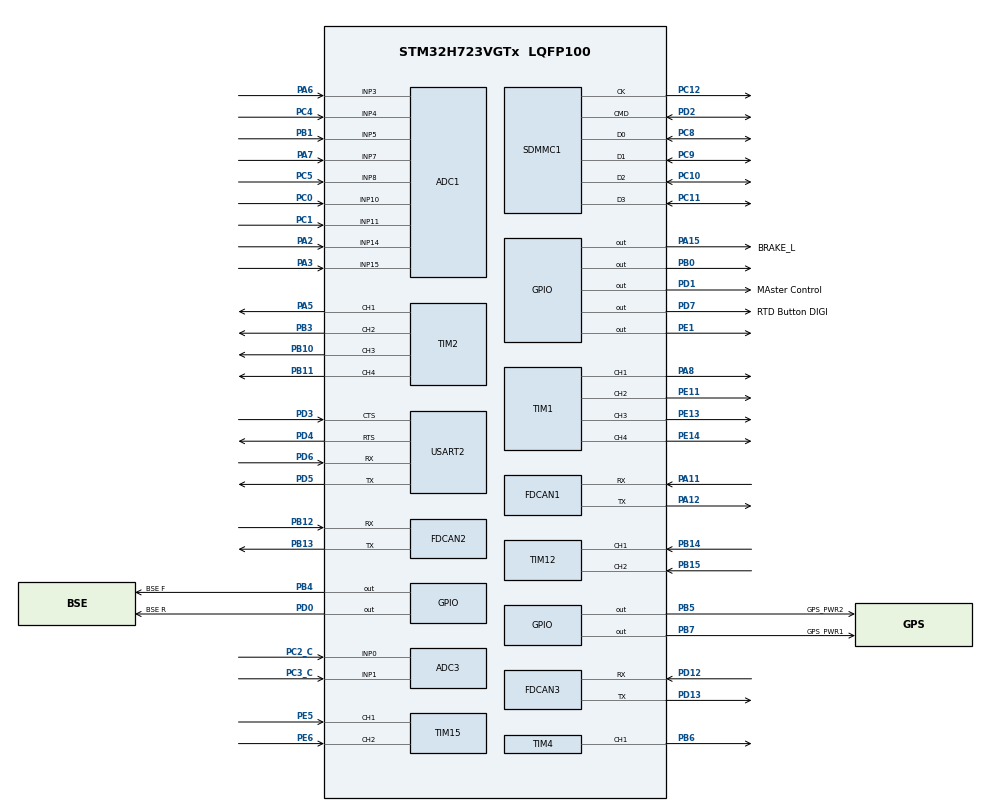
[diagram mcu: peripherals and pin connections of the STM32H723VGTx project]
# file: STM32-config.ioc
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ADC1.Channel-0\#ChannelRegularConversion=ADC_CHANNEL_15
ADC1.ClockPrescaler=ADC_CLOCK_SYNC_PCLK_DIV4
ADC1.ContinuousConvMode=ENABLE
ADC1.ConversionDataManagement=ADC_CONVERSIONDATA_DMA_CIRCULAR
ADC1.DMAAccessModeView=ENABLE
ADC1.Mode=ADC_DUALMODE_REGSIMULT
ADC1.NbrOfConversion=1
ADC1.NbrOfConversionFlag=1
ADC1.OffsetNumber-0\#ChannelRegularConversion=ADC_OFFSET_NONE
ADC1.OffsetSignedSaturation-0\#ChannelRegularConversion=DISABLE
ADC1.OversamplingMode=DISABLE
ADC1.Rank-0\#ChannelRegularConversion=1
ADC1.Ratio=1
ADC1.SamplingTime-0\#ChannelRegularConversion=ADC_SAMPLETIME_64CYCLES_5
ADC1.master=1
ADC2.Channel-0\#ChannelRegularConversion=ADC_CHANNEL_15
ADC2.ClockPrescaler=ADC_CLOCK_SYNC_PCLK_DIV4
ADC2.ContinuousConvMode=ENABLE
ADC2.ConversionDataManagement=ADC_CONVERSIONDATA_DMA_CIRCULAR
ADC2.DMAAccessModeView=ENABLE
ADC2.Mode=ADC_DUALMODE_REGSIMULT
ADC2.NbrOfConversionFlag=1
ADC2.OffsetNumber-0\#ChannelRegularConversion=ADC_OFFSET_NONE
ADC2.OffsetSignedSaturation-0\#ChannelRegularConversion=DISABLE
ADC2.Rank-0\#ChannelRegularConversion=1
ADC2.SamplingTime-0\#ChannelRegularConversion=ADC_SAMPLETIME_64CYCLES_5
ADC3.Channel-0\#ChannelRegularConversion=ADC_CHANNEL_0
ADC3.ClockPrescaler=ADC_CLOCK_SYNC_PCLK_DIV4
ADC3.DMAAccessModeView=ENABLE
ADC3.Mode=ADC_DUALMODE_REGSIMULT
ADC3.NbrOfConversionFlag=1
ADC3.OffsetNumber-0\#ChannelRegularConversion=ADC_OFFSET_NONE
ADC3.OffsetSign-0\#ChannelRegularConversion=ADC3_OFFSET_SIGN_NEGATIVE
ADC3.Rank-0\#ChannelRegularConversion=1
ADC3.SamplingTime-0\#ChannelRegularConversion=ADC3_SAMPLETIME_2CYCLES_5
CORTEX_M7.AccessPermission_Spec=MPU_REGION_FULL_ACCESS
CORTEX_M7.IsCacheable_Spec=MPU_ACCESS_CACHEABLE
CORTEX_M7.default_mode_Activation=1
Dma.ADC1.0.Direction=DMA_PERIPH_TO_MEMORY
Dma.ADC1.0.EventEnable=DISABLE
Dma.ADC1.0.FIFOMode=DMA_FIFOMODE_DISABLE
Dma.ADC1.0.Instance=DMA1_Stream0
Dma.ADC1.0.MemDataAlignment=DMA_MDATAALIGN_HALFWORD
Dma.ADC1.0.MemInc=DMA_MINC_ENABLE
Dma.ADC1.0.Mode=DMA_CIRCULAR
Dma.ADC1.0.PeriphDataAlignment=DMA_PDATAALIGN_HALFWORD
Dma.ADC1.0.PeriphInc=DMA_PINC_DISABLE
Dma.ADC1.0.Polarity=HAL_DMAMUX_REQ_GEN_RISING
Dma.ADC1.0.Priority=DMA_PRIORITY_LOW
Dma.ADC1.0.RequestNumber=1
Dma.ADC1.0.SignalID=NONE
Dma.ADC1.0.SyncEnable=DISABLE
Dma.ADC1.0.SyncPolarity=HAL_DMAMUX_SYNC_NO_EVENT
Dma.ADC1.0.SyncRequestNumber=1
Dma.ADC1.0.SyncSignalID=NONE
Dma.ADC2.1.Direction=DMA_PERIPH_TO_MEMORY
Dma.ADC2.1.EventEnable=DISABLE
Dma.ADC2.1.FIFOMode=DMA_FIFOMODE_DISABLE
Dma.ADC2.1.Instance=DMA1_Stream1
Dma.ADC2.1.MemDataAlignment=DMA_MDATAALIGN_HALFWORD
Dma.ADC2.1.MemInc=DMA_MINC_ENABLE
Dma.ADC2.1.Mode=DMA_CIRCULAR
Dma.ADC2.1.PeriphDataAlignment=DMA_PDATAALIGN_HALFWORD
Dma.ADC2.1.PeriphInc=DMA_PINC_DISABLE
Dma.ADC2.1.Polarity=HAL_DMAMUX_REQ_GEN_RISING
Dma.ADC2.1.Priority=DMA_PRIORITY_LOW
Dma.ADC2.1.RequestNumber=1
Dma.ADC2.1.SignalID=NONE
Dma.ADC2.1.SyncEnable=DISABLE
Dma.ADC2.1.SyncPolarity=HAL_DMAMUX_SYNC_NO_EVENT
Dma.ADC2.1.SyncRequestNumber=1
Dma.ADC2.1.SyncSignalID=NONE
Dma.Request0=ADC1
Dma.Request1=ADC2
FDCAN1.CalculateBaudRateNominal=2864583
FDCAN1.CalculateTimeBitNominal=349
FDCAN1.CalculateTimeQuantumNominal=116.36363636363636
FDCAN1.TxBuffersNbr=32
FDCAN2.CalculateBaudRateNominal=2864583
FDCAN2.CalculateTimeBitNominal=349
FDCAN2.CalculateTimeQuantumNominal=116.36363636363636
FDCAN2.TxBuffersNbr=32
FDCAN3.CalculateBaudRateNominal=2864583
FDCAN3.CalculateTimeBitNominal=349
FDCAN3.CalculateTimeQuantumNominal=116.36363636363636
FDCAN3.TxBuffersNbr=32
FREERTOS.Tasks01=defaultTask,24,128,StartDefaultTask,Default,NULL,Dynamic,NULL,NULL;ADCTask,35,128,StartADCTask,Default,NULL,Dynamic,NULL,NULL
Mcu.Family=STM32H7
Mcu.Name=STM32H723VGTx
Mcu.Package=LQFP100
Mdma.MDMA_Channel0.Request0=SW
Mdma.MDMA_Channel0.RequestsNb=1
Mdma.MDMA_Channel0.SW.0.BlockCount=0
Mdma.MDMA_Channel0.SW.0.BlockDataLength=0
Mdma.MDMA_Channel0.SW.0.BufferTransferLength=1
Mdma.MDMA_Channel0.SW.0.CircularMode=MDMA_LINEAR_LIST
Mdma.MDMA_Channel0.SW.0.DataAlignment=MDMA_DATAALIGN_PACKENABLE
Mdma.MDMA_Channel0.SW.0.DestBlockAddressOffset=0
Mdma.MDMA_Channel0.SW.0.DestBurst=MDMA_DEST_BURST_SINGLE
Mdma.MDMA_Channel0.SW.0.DestDataSize=MDMA_DEST_DATASIZE_BYTE
Mdma.MDMA_Channel0.SW.0.DestinationInc=MDMA_DEST_INC_BYTE
Mdma.MDMA_Channel0.SW.0.DstAddress=0
Mdma.MDMA_Channel0.SW.0.Endianness=MDMA_LITTLE_ENDIANNESS_PRESERVE
Mdma.MDMA_Channel0.SW.0.Instance=MDMA_Channel0
Mdma.MDMA_Channel0.SW.0.MaskAddress=0
Mdma.MDMA_Channel0.SW.0.MaskData=0
Mdma.MDMA_Channel0.SW.0.Priority=MDMA_PRIORITY_LOW
Mdma.MDMA_Channel0.SW.0.Rank=First
Mdma.MDMA_Channel0.SW.0.SourceBlockAddressOffset=0
Mdma.MDMA_Channel0.SW.0.SourceBurst=MDMA_SOURCE_BURST_SINGLE
Mdma.MDMA_Channel0.SW.0.SourceDataSize=MDMA_SRC_DATASIZE_BYTE
Mdma.MDMA_Channel0.SW.0.SourceInc=MDMA_SRC_INC_BYTE
Mdma.MDMA_Channel0.SW.0.SrcAddress=0
Mdma.MDMA_Channel0.SW.0.TransferTriggerMode=MDMA_BUFFER_TRANSFER
Mdma.RequestSet0=MDMA_Channel0
Mdma.RequestSetsNb=1
NVIC.ADC_IRQn=true\:5\:0\:false\:false\:true\:true\:true\:true\:true
NVIC.DMA1_Stream0_IRQn=true\:5\:0\:false\:false\:true\:true\:false\:true\:true
NVIC.DMA1_Stream1_IRQn=true\:5\:0\:false\:false\:true\:true\:false\:true\:true
NVIC.MDMA_IRQn=true\:5\:0\:false\:false\:true\:true\:false\:true\:true
NVIC.PriorityGroup=NVIC_PRIORITYGROUP_4
NVIC.TIM3_IRQn=true\:15\:0\:false\:false\:true\:false\:false\:true\:true
NVIC.TimeBase=TIM3_IRQn
NVIC.TimeBaseIP=TIM3
PA11.Mode=FDCAN_Activate
PA11.Signal=FDCAN1_RX
PA12.Mode=FDCAN_Activate
PA12.Signal=FDCAN1_TX
PA15(JTDI).GPIO_Label=BRAKE_L
PA15(JTDI).Signal=GPIO_Output
PA2.Signal=ADCx_INP14
PA3.GPIO_Pd=GPIO_NOPULL
PA3.Signal=ADCx_INP15
PA5.Signal=S_TIM2_CH1_ETR
PA6.Signal=ADCx_INP3
PA7.Signal=ADCx_INP7
PA8.Signal=S_TIM1_CH1
PB0.Signal=GPIO_Output
PB1.Signal=ADCx_INP5
PB10.Signal=S_TIM2_CH3
PB11.Signal=S_TIM2_CH4
PB12.Mode=FDCAN_Activate
PB12.Signal=FDCAN2_RX
PB13.Mode=FDCAN_Activate
PB13.Signal=FDCAN2_TX
PB14.Signal=S_TIM12_CH1
PB15.Signal=S_TIM12_CH2
PB3(JTDO/TRACESWO).Signal=S_TIM2_CH2
PB4(NJTRST).GPIO_Label=BSE F
PB4(NJTRST).Signal=GPIO_Output
PB5.GPIO_Label=GPS_PWR2
PB5.Signal=GPIO_Output
PB6.Signal=S_TIM4_CH1
PB7.GPIO_Label=GPS_PWR1
PB7.Signal=GPIO_Output
PC0.Signal=ADCx_INP10
PC1.Signal=ADCx_INP11
PC10.Mode=SD_4_bits_Wide_bus
PC10.Signal=SDMMC1_D2
PC11.Mode=SD_4_bits_Wide_bus
PC11.Signal=SDMMC1_D3
PC12.Mode=SD_4_bits_Wide_bus
PC12.Signal=SDMMC1_CK
PC2_C.Mode=IN0-Single-Ended
PC2_C.Signal=ADC3_INP0
PC3_C.Mode=IN1-Single-Ended
PC3_C.Signal=ADC3_INP1
PC4.Signal=ADCx_INP4
PC5.Signal=ADCx_INP8
PC8.Mode=SD_4_bits_Wide_bus
PC8.Signal=SDMMC1_D0
PC9.Mode=SD_4_bits_Wide_bus
PC9.Signal=SDMMC1_D1
PD0.GPIO_Label=BSE R
PD0.Signal=GPIO_Output
PD1.GPIO_Label=MAster Control
PD1.Signal=GPIO_Output
PD12.Mode=FDCAN_Activate
PD12.Signal=FDCAN3_RX
PD13.Mode=FDCAN_Activate
PD13.Signal=FDCAN3_TX
PD2.Mode=SD_4_bits_Wide_bus
PD2.Signal=SDMMC1_CMD
PD3.Mode=CTS_RTS
PD3.Signal=USART2_CTS
PD4.Mode=CTS_RTS
PD4.Signal=USART2_RTS
PD5.Mode=Asynchronous
PD5.Signal=USART2_TX
PD6.Mode=Asynchronous
PD6.Signal=USART2_RX
PD7.GPIO_Label=RTD Button DIGI
PD7.Signal=GPIO_Output
PE1.Signal=GPIO_Output
PE11.Signal=S_TIM1_CH2
PE13.Signal=S_TIM1_CH3
PE14.Signal=S_TIM1_CH4
PE5.Signal=S_TIM15_CH1
PE6.Signal=S_TIM15_CH2
PH0-OSC_IN.Mode=HSE-External-Oscillator
PH0-OSC_IN.Signal=RCC_OSC_IN
PH1-OSC_OUT.Mode=HSE-External-Oscillator
PH1-OSC_OUT.Signal=RCC_OSC_OUT
ProjectManager.HeapSize=0x200
ProjectManager.StackSize=0x400
ProjectManager.TargetToolchain=CMake
RAMECC.Instance-RAMECC1_Monitor1=RAMECC1_Monitor1
RCC.ADCFreq_Value=100000000
RCC.APB1Freq_Value=137500000
RCC.APB2Freq_Value=137500000
RCC.APB3Freq_Value=137500000
RCC.APB4Freq_Value=137500000
RCC.CortexFreq_Value=550000000
RCC.D1PPRE=RCC_APB3_DIV2
RCC.D2PPRE1=RCC_APB1_DIV2
RCC.D2PPRE2=RCC_APB2_DIV2
RCC.D3PPRE=RCC_APB4_DIV2
RCC.DIVM1=2
RCC.DIVM2=2
RCC.DIVN1=44
RCC.DIVN2=16
RCC.DIVP1=1
RCC.DIVQ1=4
RCC.HCLKFreq_Value=275000000
RCC.HPRE=RCC_HCLK_DIV2
RCC.HSE_VALUE=25000000
RCC.PLL2FRACN=0
RCC.PLLFRACN=0
RCC.PLLSourceVirtual=RCC_PLLSOURCE_HSE
RCC.SYSCLKFreq_VALUE=550000000
RCC.SYSCLKSource=RCC_SYSCLKSOURCE_PLLCLK
RCC.USBFreq_Value=137500000
SH.ADCx_INP10.0=ADC1_INP10,IN10-Single-Ended
SH.ADCx_INP11.0=ADC1_INP11,IN11-Single-Ended
SH.ADCx_INP14.0=ADC1_INP14,IN14-Single-Ended
SH.ADCx_INP15.0=ADC1_INP15,IN15-Single-Ended
SH.ADCx_INP15.1=ADC2_INP15,IN15-Single-Ended
SH.ADCx_INP3.0=ADC1_INP3,IN3-Single-Ended
SH.ADCx_INP3.1=ADC2_INP3,IN3-Single-Ended
SH.ADCx_INP4.0=ADC1_INP4,IN4-Single-Ended
SH.ADCx_INP4.1=ADC2_INP4,IN4-Single-Ended
SH.ADCx_INP5.0=ADC1_INP5,IN5-Single-Ended
SH.ADCx_INP7.0=ADC1_INP7,IN7-Single-Ended
SH.ADCx_INP8.0=ADC1_INP8,IN8-Single-Ended
SH.S_TIM12_CH1.0=TIM12_CH1,Input_Capture1_from_TI1
SH.S_TIM12_CH2.0=TIM12_CH2,Input_Capture2_from_TI2
SH.S_TIM15_CH1.0=TIM15_CH1,Input_Capture1_from_TI1
SH.S_TIM15_CH2.0=TIM15_CH2,Input_Capture2_from_TI2
SH.S_TIM1_CH1.0=TIM1_CH1,PWM Generation1 CH1
SH.S_TIM1_CH2.0=TIM1_CH2,PWM Generation2 CH2
SH.S_TIM1_CH3.0=TIM1_CH3,PWM Generation3 CH3
SH.S_TIM1_CH4.0=TIM1_CH4,PWM Generation4 CH4
SH.S_TIM2_CH1_ETR.0=TIM2_CH1,PWM Generation1 CH1
SH.S_TIM2_CH2.0=TIM2_CH2,PWM Generation2 CH2
SH.S_TIM2_CH3.0=TIM2_CH3,PWM Generation3 CH3
SH.S_TIM2_CH4.0=TIM2_CH4,PWM Generation4 CH4
SH.S_TIM4_CH1.0=TIM4_CH1,PWM Generation1 CH1
TIM1.Channel-PWM\ Generation1\ CH1=TIM_CHANNEL_1
TIM1.Channel-PWM\ Generation2\ CH2=TIM_CHANNEL_2
TIM1.Channel-PWM\ Generation3\ CH3=TIM_CHANNEL_3
TIM1.Channel-PWM\ Generation4\ CH4=TIM_CHANNEL_4
TIM12.Channel-Input_Capture1_from_TI1=TIM_CHANNEL_1
TIM12.Channel-Input_Capture2_from_TI2=TIM_CHANNEL_2
TIM15.Channel-Input_Capture1_from_TI1=TIM_CHANNEL_1
TIM15.Channel-Input_Capture2_from_TI2=TIM_CHANNEL_2
TIM2.Channel-PWM\ Generation1\ CH1=TIM_CHANNEL_1
TIM2.Channel-PWM\ Generation2\ CH2=TIM_CHANNEL_2
TIM2.Channel-PWM\ Generation3\ CH3=TIM_CHANNEL_3
TIM2.Channel-PWM\ Generation4\ CH4=TIM_CHANNEL_4
TIM4.Channel-PWM\ Generation1\ CH1=TIM_CHANNEL_1
TIM5.Channel-Input_Capture1_from_TI1_Remap_TIM5=TIM_CHANNEL_1
USART2.VirtualMode-Asynchronous=VM_ASYNC
VP_FREERTOS_VS_CMSIS_V2.Mode=CMSIS_V2
VP_MEMORYMAP_VS_MEMORYMAP.Mode=CurAppReg
VP_RAMECC_VS_D1_1.Mode=RAMECC1_Monitor1
VP_SYS_VS_tim3.Mode=TIM3
VP_TIM5_VS_NoInput1.Mode=Input_Capture1_from_TI1_Remap_TIM5
board=custom

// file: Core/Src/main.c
/* USER CODE BEGIN Header */
/**
  ******************************************************************************
  * @file           : main.c
  * @brief          : Main program body
  ******************************************************************************
  * @attention
  *
  * Copyright (c) 2026 STMicroelectronics.
  * All rights reserved.
  *
  * This software is licensed under terms that can be found in the LICENSE file
  * in the root directory of this software component.
  * If no LICENSE file comes with this software, it is provided AS-IS.
  *
  ******************************************************************************
  */
/* USER CODE END Header */
#include "main.h"
#include "cmsis_os.h"
#include "projdefs.h"

/* USER CODE BEGIN PD */
#define D2_RAM __attribute__((section(".D2_RAM")))
/* USER CODE END PD */

ADC_HandleTypeDef hadc1;
ADC_HandleTypeDef hadc2;
ADC_HandleTypeDef hadc3;
DMA_HandleTypeDef hdma_adc1;
DMA_HandleTypeDef hdma_adc2;

FDCAN_HandleTypeDef hfdcan1;
FDCAN_HandleTypeDef hfdcan2;
FDCAN_HandleTypeDef hfdcan3;

RAMECC_HandleTypeDef hramecc1_m1;

SD_HandleTypeDef hsd1;

TIM_HandleTypeDef htim1;
TIM_HandleTypeDef htim2;
TIM_HandleTypeDef htim4;
TIM_HandleTypeDef htim5;
TIM_HandleTypeDef htim12;
TIM_HandleTypeDef htim15;

UART_HandleTypeDef huart2;

MDMA_HandleTypeDef hmdma_mdma_channel0_sw_0;
/* Definitions for defaultTask */
osThreadId_t defaultTaskHandle;
const osThreadAttr_t defaultTask_attributes = {
  .name = "defaultTask",
  .stack_size = 128 * 4,
  .priority = (osPriority_t) osPriorityNormal,
};
/* Definitions for ADCTask */
osThreadId_t ADCTaskHandle;
const osThreadAttr_t ADCTask_attributes = {
  .name = "ADCTask",
  .stack_size = 128 * 4,
  .priority = (osPriority_t) osPriorityAboveNormal3,
};
/* USER CODE BEGIN PV */
D2_RAM uint32_t raw[16];
uint16_t adc1, adc2;
/* USER CODE END PV */

void SystemClock_Config(void);
static void MPU_Config(void);
static void MX_GPIO_Init(void);
static void MX_MDMA_Init(void);
static void MX_DMA_Init(void);
static void MX_ADC1_Init(void);
static void MX_FDCAN1_Init(void);
static void MX_FDCAN2_Init(void);
static void MX_FDCAN3_Init(void);
static void MX_TIM1_Init(void);
static void MX_TIM2_Init(void);
static void MX_TIM4_Init(void);
static void MX_TIM5_Init(void);
static void MX_TIM15_Init(void);
static void MX_RAMECC_Init(void);
static void MX_USART2_UART_Init(void);
static void MX_ADC2_Init(void);
static void MX_ADC3_Init(void);
static void MX_SDMMC1_SD_Init(void);
static void MX_TIM12_Init(void);
void StartDefaultTask(void *argument);
void StartADCTask(void *argument);

/* USER CODE BEGIN PFP */
void CAN_TX(void);
/* USER CODE END PFP */

int main(void)
{

  /* MPU Configuration--------------------------------------------------------*/
  MPU_Config();

  /* MCU Configuration--------------------------------------------------------*/

  /* Reset of all peripherals, Initializes the Flash interface and the Systick. */
  HAL_Init();

  /* Configure the system clock */
  SystemClock_Config();

  /* Initialize all configured peripherals */
  MX_GPIO_Init();
  MX_MDMA_Init();
  MX_DMA_Init();
  MX_ADC1_Init();
  MX_FDCAN1_Init();
  MX_FDCAN2_Init();
  MX_FDCAN3_Init();
  MX_TIM1_Init();
  MX_TIM2_Init();
  MX_TIM4_Init();
  MX_TIM5_Init();
  MX_TIM15_Init();
  MX_RAMECC_Init();
  MX_USART2_UART_Init();
  MX_ADC2_Init();
  MX_ADC3_Init();
  MX_TIM12_Init();
  /* USER CODE BEGIN 2 */
  if (HAL_GPIO_ReadPin(GPIOC, 11) == 1) {
    MX_SDMMC1_SD_Init();
  }

  HAL_ADCEx_Calibration_Start(&hadc1, ADC_CALIB_OFFSET, ADC_SINGLE_ENDED);
  /* USER CODE END 2 */

  /* Init scheduler */
  osKernelInitialize();

  /* Create the thread(s) */
  /* creation of defaultTask */
  defaultTaskHandle = osThreadNew(StartDefaultTask, NULL, &defaultTask_attributes);

  /* creation of ADCTask */
  ADCTaskHandle = osThreadNew(StartADCTask, NULL, &ADCTask_attributes);

  /* Start scheduler */
  osKernelStart();

  /* We should never get here as control is now taken by the scheduler */

  /* Infinite loop */
  while (1)
  {

  }
}

void SystemClock_Config(void)
{
  RCC_OscInitTypeDef RCC_OscInitStruct = {0};
  RCC_ClkInitTypeDef RCC_ClkInitStruct = {0};

  /** Supply configuration update enable
  */
  HAL_PWREx_ConfigSupply(PWR_LDO_SUPPLY);

  /** Configure the main internal regulator output voltage
  */
  __HAL_PWR_VOLTAGESCALING_CONFIG(PWR_REGULATOR_VOLTAGE_SCALE0);

  while(!__HAL_PWR_GET_FLAG(PWR_FLAG_VOSRDY)) {}

  /** Initializes the RCC Oscillators according to the specified parameters
  * in the RCC_OscInitTypeDef structure.
  */
  RCC_OscInitStruct.OscillatorType = RCC_OSCILLATORTYPE_HSE;
  RCC_OscInitStruct.HSEState = RCC_HSE_ON;
  RCC_OscInitStruct.PLL.PLLState = RCC_PLL_ON;
  RCC_OscInitStruct.PLL.PLLSource = RCC_PLLSOURCE_HSE;
  RCC_OscInitStruct.PLL.PLLM = 2;
  RCC_OscInitStruct.PLL.PLLN = 44;
  RCC_OscInitStruct.PLL.PLLP = 1;
  RCC_OscInitStruct.PLL.PLLQ = 4;
  RCC_OscInitStruct.PLL.PLLR = 2;
  RCC_OscInitStruct.PLL.PLLRGE = RCC_PLL1VCIRANGE_3;
  RCC_OscInitStruct.PLL.PLLVCOSEL = RCC_PLL1VCOWIDE;
  RCC_OscInitStruct.PLL.PLLFRACN = 0;
  if (HAL_RCC_OscConfig(&RCC_OscInitStruct) != HAL_OK)
  {
    Error_Handler();
  }

  /** Initializes the CPU, AHB and APB buses clocks
  */
  RCC_ClkInitStruct.ClockType = RCC_CLOCKTYPE_HCLK|RCC_CLOCKTYPE_SYSCLK
                              |RCC_CLOCKTYPE_PCLK1|RCC_CLOCKTYPE_PCLK2
                              |RCC_CLOCKTYPE_D3PCLK1|RCC_CLOCKTYPE_D1PCLK1;
  RCC_ClkInitStruct.SYSCLKSource = RCC_SYSCLKSOURCE_PLLCLK;
  RCC_ClkInitStruct.SYSCLKDivider = RCC_SYSCLK_DIV1;
  RCC_ClkInitStruct.AHBCLKDivider = RCC_HCLK_DIV2;
  RCC_ClkInitStruct.APB3CLKDivider = RCC_APB3_DIV2;
  RCC_ClkInitStruct.APB1CLKDivider = RCC_APB1_DIV2;
  RCC_ClkInitStruct.APB2CLKDivider = RCC_APB2_DIV2;
  RCC_ClkInitStruct.APB4CLKDivider = RCC_APB4_DIV2;

  if (HAL_RCC_ClockConfig(&RCC_ClkInitStruct, FLASH_LATENCY_3) != HAL_OK)
  {
    Error_Handler();
  }
}

static void MX_ADC1_Init(void)
{

  ADC_MultiModeTypeDef multimode = {0};
  ADC_ChannelConfTypeDef sConfig = {0};

  /** Common config
  */
  hadc1.Instance = ADC1;
  hadc1.Init.ClockPrescaler = ADC_CLOCK_SYNC_PCLK_DIV4;
  hadc1.Init.Resolution = ADC_RESOLUTION_16B;
  hadc1.Init.ScanConvMode = ADC_SCAN_DISABLE;
  hadc1.Init.EOCSelection = ADC_EOC_SINGLE_CONV;
  hadc1.Init.LowPowerAutoWait = DISABLE;
  hadc1.Init.ContinuousConvMode = ENABLE;
  hadc1.Init.NbrOfConversion = 1;
  hadc1.Init.DiscontinuousConvMode = DISABLE;
  hadc1.Init.ExternalTrigConv = ADC_SOFTWARE_START;
  hadc1.Init.ExternalTrigConvEdge = ADC_EXTERNALTRIGCONVEDGE_NONE;
  hadc1.Init.ConversionDataManagement = ADC_CONVERSIONDATA_DMA_CIRCULAR;
  hadc1.Init.Overrun = ADC_OVR_DATA_PRESERVED;
  hadc1.Init.LeftBitShift = ADC_LEFTBITSHIFT_NONE;
  hadc1.Init.OversamplingMode = DISABLE;
  hadc1.Init.Oversampling.Ratio = 1;
  if (HAL_ADC_Init(&hadc1) != HAL_OK)
  {
    Error_Handler();
  }

  /** Configure the ADC multi-mode
  */
  multimode.Mode = ADC_DUALMODE_REGSIMULT;
  multimode.DualModeData = ADC_DUALMODEDATAFORMAT_32_10_BITS;
  multimode.TwoSamplingDelay = ADC_TWOSAMPLINGDELAY_1CYCLE;
  if (HAL_ADCEx_MultiModeConfigChannel(&hadc1, &multimode) != HAL_OK)
  {
    Error_Handler();
  }

  /** Configure Regular Channel
  */
  sConfig.Channel = ADC_CHANNEL_15;
  sConfig.Rank = ADC_REGULAR_RANK_1;
  sConfig.SamplingTime = ADC_SAMPLETIME_64CYCLES_5;
  sConfig.SingleDiff = ADC_SINGLE_ENDED;
  sConfig.OffsetNumber = ADC_OFFSET_NONE;
  sConfig.Offset = 0;
  sConfig.OffsetSignedSaturation = DISABLE;
  if (HAL_ADC_ConfigChannel(&hadc1, &sConfig) != HAL_OK)
  {
    Error_Handler();
  }

}

static void MX_ADC2_Init(void)
{

  ADC_ChannelConfTypeDef sConfig = {0};

  /** Common config
  */
  hadc2.Instance = ADC2;
  hadc2.Init.ClockPrescaler = ADC_CLOCK_SYNC_PCLK_DIV4;
  hadc2.Init.Resolution = ADC_RESOLUTION_16B;
  hadc2.Init.ScanConvMode = ADC_SCAN_DISABLE;
  hadc2.Init.EOCSelection = ADC_EOC_SINGLE_CONV;
  hadc2.Init.LowPowerAutoWait = DISABLE;
  hadc2.Init.ContinuousConvMode = ENABLE;
  hadc2.Init.NbrOfConversion = 1;
  hadc2.Init.DiscontinuousConvMode = DISABLE;
  hadc2.Init.ConversionDataManagement = ADC_CONVERSIONDATA_DMA_CIRCULAR;
  hadc2.Init.Overrun = ADC_OVR_DATA_PRESERVED;
  hadc2.Init.LeftBitShift = ADC_LEFTBITSHIFT_NONE;
  hadc2.Init.OversamplingMode = DISABLE;
  hadc2.Init.Oversampling.Ratio = 1;
  if (HAL_ADC_Init(&hadc2) != HAL_OK)
  {
    Error_Handler();
  }

  /** Configure Regular Channel
  */
  sConfig.Channel = ADC_CHANNEL_15;
  sConfig.Rank = ADC_REGULAR_RANK_1;
  sConfig.SamplingTime = ADC_SAMPLETIME_64CYCLES_5;
  sConfig.SingleDiff = ADC_SINGLE_ENDED;
  sConfig.OffsetNumber = ADC_OFFSET_NONE;
  sConfig.Offset = 0;
  sConfig.OffsetSignedSaturation = DISABLE;
  if (HAL_ADC_ConfigChannel(&hadc2, &sConfig) != HAL_OK)
  {
    Error_Handler();
  }

}

static void MX_ADC3_Init(void)
{

  ADC_ChannelConfTypeDef sConfig = {0};

  /** Common config
  */
  hadc3.Instance = ADC3;
  hadc3.Init.ClockPrescaler = ADC_CLOCK_ASYNC_DIV1;
  hadc3.Init.Resolution = ADC_RESOLUTION_12B;
  hadc3.Init.DataAlign = ADC3_DATAALIGN_RIGHT;
  hadc3.Init.ScanConvMode = ADC_SCAN_DISABLE;
  hadc3.Init.EOCSelection = ADC_EOC_SINGLE_CONV;
  hadc3.Init.LowPowerAutoWait = DISABLE;
  hadc3.Init.ContinuousConvMode = DISABLE;
  hadc3.Init.NbrOfConversion = 1;
  hadc3.Init.DiscontinuousConvMode = DISABLE;
  hadc3.Init.ExternalTrigConv = ADC_SOFTWARE_START;
  hadc3.Init.ExternalTrigConvEdge = ADC_EXTERNALTRIGCONVEDGE_NONE;
  hadc3.Init.DMAContinuousRequests = DISABLE;
  hadc3.Init.SamplingMode = ADC_SAMPLING_MODE_NORMAL;
  hadc3.Init.ConversionDataManagement = ADC_CONVERSIONDATA_DR;
  hadc3.Init.Overrun = ADC_OVR_DATA_PRESERVED;
  hadc3.Init.LeftBitShift = ADC_LEFTBITSHIFT_NONE;
  hadc3.Init.OversamplingMode = DISABLE;
  hadc3.Init.Oversampling.Ratio = ADC3_OVERSAMPLING_RATIO_2;
  if (HAL_ADC_Init(&hadc3) != HAL_OK)
  {
    Error_Handler();
  }

  /** Configure Regular Channel
  */
  sConfig.Channel = ADC_CHANNEL_0;
  sConfig.Rank = ADC_REGULAR_RANK_1;
  sConfig.SamplingTime = ADC3_SAMPLETIME_2CYCLES_5;
  sConfig.SingleDiff = ADC_SINGLE_ENDED;
  sConfig.OffsetNumber = ADC_OFFSET_NONE;
  sConfig.Offset = 0;
  sConfig.OffsetSign = ADC3_OFFSET_SIGN_NEGATIVE;
  if (HAL_ADC_ConfigChannel(&hadc3, &sConfig) != HAL_OK)
  {
    Error_Handler();
  }

}

static void MX_FDCAN1_Init(void)
{

  hfdcan1.Instance = FDCAN1;
  hfdcan1.Init.FrameFormat = FDCAN_FRAME_CLASSIC;
  hfdcan1.Init.Mode = FDCAN_MODE_NORMAL;
  hfdcan1.Init.AutoRetransmission = DISABLE;
  hfdcan1.Init.TransmitPause = DISABLE;
  hfdcan1.Init.ProtocolException = DISABLE;
  hfdcan1.Init.NominalPrescaler = 16;
  hfdcan1.Init.NominalSyncJumpWidth = 1;
  hfdcan1.Init.NominalTimeSeg1 = 1;
  hfdcan1.Init.NominalTimeSeg2 = 1;
  hfdcan1.Init.DataPrescaler = 1;
  hfdcan1.Init.DataSyncJumpWidth = 1;
  hfdcan1.Init.DataTimeSeg1 = 1;
  hfdcan1.Init.DataTimeSeg2 = 1;
  hfdcan1.Init.MessageRAMOffset = 0;
  hfdcan1.Init.StdFiltersNbr = 0;
  hfdcan1.Init.ExtFiltersNbr = 0;
  hfdcan1.Init.RxFifo0ElmtsNbr = 0;
  hfdcan1.Init.RxFifo0ElmtSize = FDCAN_DATA_BYTES_8;
  hfdcan1.Init.RxFifo1ElmtsNbr = 0;
  hfdcan1.Init.RxFifo1ElmtSize = FDCAN_DATA_BYTES_8;
  hfdcan1.Init.RxBuffersNbr = 0;
  hfdcan1.Init.RxBufferSize = FDCAN_DATA_BYTES_8;
  hfdcan1.Init.TxEventsNbr = 0;
  hfdcan1.Init.TxBuffersNbr = 32;
  hfdcan1.Init.TxFifoQueueElmtsNbr = 0;
  hfdcan1.Init.TxFifoQueueMode = FDCAN_TX_FIFO_OPERATION;
  hfdcan1.Init.TxElmtSize = FDCAN_DATA_BYTES_8;
  if (HAL_FDCAN_Init(&hfdcan1) != HAL_OK)
  {
    Error_Handler();
  }

}

static void MX_FDCAN2_Init(void)
{

  hfdcan2.Instance = FDCAN2;
  hfdcan2.Init.FrameFormat = FDCAN_FRAME_CLASSIC;
  hfdcan2.Init.Mode = FDCAN_MODE_NORMAL;
  hfdcan2.Init.AutoRetransmission = DISABLE;
  hfdcan2.Init.TransmitPause = DISABLE;
  hfdcan2.Init.ProtocolException = DISABLE;
  hfdcan2.Init.NominalPrescaler = 16;
  hfdcan2.Init.NominalSyncJumpWidth = 1;
  hfdcan2.Init.NominalTimeSeg1 = 1;
  hfdcan2.Init.NominalTimeSeg2 = 1;
  hfdcan2.Init.DataPrescaler = 1;
  hfdcan2.Init.DataSyncJumpWidth = 1;
  hfdcan2.Init.DataTimeSeg1 = 1;
  hfdcan2.Init.DataTimeSeg2 = 1;
  hfdcan2.Init.MessageRAMOffset = 0;
  hfdcan2.Init.StdFiltersNbr = 0;
  hfdcan2.Init.ExtFiltersNbr = 0;
  hfdcan2.Init.RxFifo0ElmtsNbr = 0;
  hfdcan2.Init.RxFifo0ElmtSize = FDCAN_DATA_BYTES_8;
  hfdcan2.Init.RxFifo1ElmtsNbr = 0;
  hfdcan2.Init.RxFifo1ElmtSize = FDCAN_DATA_BYTES_8;
  hfdcan2.Init.RxBuffersNbr = 0;
  hfdcan2.Init.RxBufferSize = FDCAN_DATA_BYTES_8;
  hfdcan2.Init.TxEventsNbr = 0;
  hfdcan2.Init.TxBuffersNbr = 32;
  hfdcan2.Init.TxFifoQueueElmtsNbr = 0;
  hfdcan2.Init.TxFifoQueueMode = FDCAN_TX_FIFO_OPERATION;
  hfdcan2.Init.TxElmtSize = FDCAN_DATA_BYTES_8;
  if (HAL_FDCAN_Init(&hfdcan2) != HAL_OK)
  {
    Error_Handler();
  }

}

static void MX_FDCAN3_Init(void)
{

  hfdcan3.Instance = FDCAN3;
  hfdcan3.Init.FrameFormat = FDCAN_FRAME_CLASSIC;
  hfdcan3.Init.Mode = FDCAN_MODE_NORMAL;
  hfdcan3.Init.AutoRetransmission = DISABLE;
  hfdcan3.Init.TransmitPause = DISABLE;
  hfdcan3.Init.ProtocolException = DISABLE;
  hfdcan3.Init.NominalPrescaler = 16;
  hfdcan3.Init.NominalSyncJumpWidth = 1;
  hfdcan3.Init.NominalTimeSeg1 = 1;
  hfdcan3.Init.NominalTimeSeg2 = 1;
  hfdcan3.Init.DataPrescaler = 1;
  hfdcan3.Init.DataSyncJumpWidth = 1;
  hfdcan3.Init.DataTimeSeg1 = 1;
  hfdcan3.Init.DataTimeSeg2 = 1;
  hfdcan3.Init.MessageRAMOffset = 0;
  hfdcan3.Init.StdFiltersNbr = 0;
  hfdcan3.Init.ExtFiltersNbr = 0;
  hfdcan3.Init.RxFifo0ElmtsNbr = 0;
  hfdcan3.Init.RxFifo0ElmtSize = FDCAN_DATA_BYTES_8;
  hfdcan3.Init.RxFifo1ElmtsNbr = 0;
  hfdcan3.Init.RxFifo1ElmtSize = FDCAN_DATA_BYTES_8;
  hfdcan3.Init.RxBuffersNbr = 0;
  hfdcan3.Init.RxBufferSize = FDCAN_DATA_BYTES_8;
  hfdcan3.Init.TxEventsNbr = 0;
  hfdcan3.Init.TxBuffersNbr = 32;
  hfdcan3.Init.TxFifoQueueElmtsNbr = 0;
  hfdcan3.Init.TxFifoQueueMode = FDCAN_TX_FIFO_OPERATION;
  hfdcan3.Init.TxElmtSize = FDCAN_DATA_BYTES_8;
  if (HAL_FDCAN_Init(&hfdcan3) != HAL_OK)
  {
    Error_Handler();
  }

}

static void MX_RAMECC_Init(void)
{

  /** Initialize RAMECC1 M1 : AXI SRAM
  */
  hramecc1_m1.Instance = RAMECC1_Monitor1;
  if (HAL_RAMECC_Init(&hramecc1_m1) != HAL_OK)
  {
    Error_Handler();
  }

}

static void MX_SDMMC1_SD_Init(void)
{

  hsd1.Instance = SDMMC1;
  hsd1.Init.ClockEdge = SDMMC_CLOCK_EDGE_RISING;
  hsd1.Init.ClockPowerSave = SDMMC_CLOCK_POWER_SAVE_DISABLE;
  hsd1.Init.BusWide = SDMMC_BUS_WIDE_4B;
  hsd1.Init.HardwareFlowControl = SDMMC_HARDWARE_FLOW_CONTROL_DISABLE;
  hsd1.Init.ClockDiv = 0;
  if (HAL_SD_Init(&hsd1) != HAL_OK)
  {
    Error_Handler();
  }

}

static void MX_TIM1_Init(void)
{

  TIM_MasterConfigTypeDef sMasterConfig = {0};
  TIM_OC_InitTypeDef sConfigOC = {0};
  TIM_BreakDeadTimeConfigTypeDef sBreakDeadTimeConfig = {0};

  htim1.Instance = TIM1;
  htim1.Init.Prescaler = 0;
  htim1.Init.CounterMode = TIM_COUNTERMODE_UP;
  htim1.Init.Period = 65535;
  htim1.Init.ClockDivision = TIM_CLOCKDIVISION_DIV1;
  htim1.Init.RepetitionCounter = 0;
  htim1.Init.AutoReloadPreload = TIM_AUTORELOAD_PRELOAD_DISABLE;
  if (HAL_TIM_PWM_Init(&htim1) != HAL_OK)
  {
    Error_Handler();
  }
  sMasterConfig.MasterOutputTrigger = TIM_TRGO_RESET;
  sMasterConfig.MasterOutputTrigger2 = TIM_TRGO2_RESET;
  sMasterConfig.MasterSlaveMode = TIM_MASTERSLAVEMODE_DISABLE;
  if (HAL_TIMEx_MasterConfigSynchronization(&htim1, &sMasterConfig) != HAL_OK)
  {
    Error_Handler();
  }
  sConfigOC.OCMode = TIM_OCMODE_PWM1;
  sConfigOC.Pulse = 0;
  sConfigOC.OCPolarity = TIM_OCPOLARITY_HIGH;
  sConfigOC.OCNPolarity = TIM_OCNPOLARITY_HIGH;
  sConfigOC.OCFastMode = TIM_OCFAST_DISABLE;
  sConfigOC.OCIdleState = TIM_OCIDLESTATE_RESET;
  sConfigOC.OCNIdleState = TIM_OCNIDLESTATE_RESET;
  if (HAL_TIM_PWM_ConfigChannel(&htim1, &sConfigOC, TIM_CHANNEL_1) != HAL_OK)
  {
    Error_Handler();
  }
  if (HAL_TIM_PWM_ConfigChannel(&htim1, &sConfigOC, TIM_CHANNEL_2) != HAL_OK)
  {
    Error_Handler();
  }
  if (HAL_TIM_PWM_ConfigChannel(&htim1, &sConfigOC, TIM_CHANNEL_3) != HAL_OK)
  {
    Error_Handler();
  }
  if (HAL_TIM_PWM_ConfigChannel(&htim1, &sConfigOC, TIM_CHANNEL_4) != HAL_OK)
  {
    Error_Handler();
  }
  sBreakDeadTimeConfig.OffStateRunMode = TIM_OSSR_DISABLE;
  sBreakDeadTimeConfig.OffStateIDLEMode = TIM_OSSI_DISABLE;
  sBreakDeadTimeConfig.LockLevel = TIM_LOCKLEVEL_OFF;
  sBreakDeadTimeConfig.DeadTime = 0;
  sBreakDeadTimeConfig.BreakState = TIM_BREAK_DISABLE;
  sBreakDeadTimeConfig.BreakPolarity = TIM_BREAKPOLARITY_HIGH;
  sBreakDeadTimeConfig.BreakFilter = 0;
  sBreakDeadTimeConfig.Break2State = TIM_BREAK2_DISABLE;
  sBreakDeadTimeConfig.Break2Polarity = TIM_BREAK2POLARITY_HIGH;
  sBreakDeadTimeConfig.Break2Filter = 0;
  sBreakDeadTimeConfig.AutomaticOutput = TIM_AUTOMATICOUTPUT_DISABLE;
  if (HAL_TIMEx_ConfigBreakDeadTime(&htim1, &sBreakDeadTimeConfig) != HAL_OK)
  {
    Error_Handler();
  }
  HAL_TIM_MspPostInit(&htim1);

}

static void MX_TIM2_Init(void)
{

  TIM_MasterConfigTypeDef sMasterConfig = {0};
  TIM_OC_InitTypeDef sConfigOC = {0};

  htim2.Instance = TIM2;
  htim2.Init.Prescaler = 0;
  htim2.Init.CounterMode = TIM_COUNTERMODE_UP;
  htim2.Init.Period = 4294967295;
  htim2.Init.ClockDivision = TIM_CLOCKDIVISION_DIV1;
  htim2.Init.AutoReloadPreload = TIM_AUTORELOAD_PRELOAD_DISABLE;
  if (HAL_TIM_PWM_Init(&htim2) != HAL_OK)
  {
    Error_Handler();
  }
  sMasterConfig.MasterOutputTrigger = TIM_TRGO_RESET;
  sMasterConfig.MasterSlaveMode = TIM_MASTERSLAVEMODE_DISABLE;
  if (HAL_TIMEx_MasterConfigSynchronization(&htim2, &sMasterConfig) != HAL_OK)
  {
    Error_Handler();
  }
  sConfigOC.OCMode = TIM_OCMODE_PWM1;
  sConfigOC.Pulse = 0;
  sConfigOC.OCPolarity = TIM_OCPOLARITY_HIGH;
  sConfigOC.OCFastMode = TIM_OCFAST_DISABLE;
  if (HAL_TIM_PWM_ConfigChannel(&htim2, &sConfigOC, TIM_CHANNEL_1) != HAL_OK)
  {
    Error_Handler();
  }
  if (HAL_TIM_PWM_ConfigChannel(&htim2, &sConfigOC, TIM_CHANNEL_2) != HAL_OK)
  {
    Error_Handler();
  }
  if (HAL_TIM_PWM_ConfigChannel(&htim2, &sConfigOC, TIM_CHANNEL_3) != HAL_OK)
  {
    Error_Handler();
  }
  if (HAL_TIM_PWM_ConfigChannel(&htim2, &sConfigOC, TIM_CHANNEL_4) != HAL_OK)
  {
    Error_Handler();
  }
  HAL_TIM_MspPostInit(&htim2);

}

static void MX_TIM4_Init(void)
{

  TIM_MasterConfigTypeDef sMasterConfig = {0};
  TIM_OC_InitTypeDef sConfigOC = {0};

  htim4.Instance = TIM4;
  htim4.Init.Prescaler = 0;
  htim4.Init.CounterMode = TIM_COUNTERMODE_UP;
  htim4.Init.Period = 65535;
  htim4.Init.ClockDivision = TIM_CLOCKDIVISION_DIV1;
  htim4.Init.AutoReloadPreload = TIM_AUTORELOAD_PRELOAD_DISABLE;
  if (HAL_TIM_PWM_Init(&htim4) != HAL_OK)
  {
    Error_Handler();
  }
  sMasterConfig.MasterOutputTrigger = TIM_TRGO_RESET;
  sMasterConfig.MasterSlaveMode = TIM_MASTERSLAVEMODE_DISABLE;
  if (HAL_TIMEx_MasterConfigSynchronization(&htim4, &sMasterConfig) != HAL_OK)
  {
    Error_Handler();
  }
  sConfigOC.OCMode = TIM_OCMODE_PWM1;
  sConfigOC.Pulse = 0;
  sConfigOC.OCPolarity = TIM_OCPOLARITY_HIGH;
  sConfigOC.OCFastMode = TIM_OCFAST_DISABLE;
  if (HAL_TIM_PWM_ConfigChannel(&htim4, &sConfigOC, TIM_CHANNEL_1) != HAL_OK)
  {
    Error_Handler();
  }
  HAL_TIM_MspPostInit(&htim4);

}

static void MX_TIM5_Init(void)
{

  TIM_MasterConfigTypeDef sMasterConfig = {0};
  TIM_IC_InitTypeDef sConfigIC = {0};

  htim5.Instance = TIM5;
  htim5.Init.Prescaler = 0;
  htim5.Init.CounterMode = TIM_COUNTERMODE_UP;
  htim5.Init.Period = 4294967295;
  htim5.Init.ClockDivision = TIM_CLOCKDIVISION_DIV1;
  htim5.Init.AutoReloadPreload = TIM_AUTORELOAD_PRELOAD_DISABLE;
  if (HAL_TIM_IC_Init(&htim5) != HAL_OK)
  {
    Error_Handler();
  }
  sMasterConfig.MasterOutputTrigger = TIM_TRGO_RESET;
  sMasterConfig.MasterSlaveMode = TIM_MASTERSLAVEMODE_DISABLE;
  if (HAL_TIMEx_MasterConfigSynchronization(&htim5, &sMasterConfig) != HAL_OK)
  {
    Error_Handler();
  }
  sConfigIC.ICPolarity = TIM_INPUTCHANNELPOLARITY_RISING;
  sConfigIC.ICSelection = TIM_ICSELECTION_DIRECTTI;
  sConfigIC.ICPrescaler = TIM_ICPSC_DIV1;
  sConfigIC.ICFilter = 0;
  if (HAL_TIM_IC_ConfigChannel(&htim5, &sConfigIC, TIM_CHANNEL_1) != HAL_OK)
  {
    Error_Handler();
  }
  if (HAL_TIMEx_TISelection(&htim5, TIM_TIM5_TI1_CAN_TMP, TIM_CHANNEL_1) != HAL_OK)
  {
    Error_Handler();
  }

}

static void MX_TIM12_Init(void)
{

  TIM_MasterConfigTypeDef sMasterConfig = {0};
  TIM_IC_InitTypeDef sConfigIC = {0};

  htim12.Instance = TIM12;
  htim12.Init.Prescaler = 0;
  htim12.Init.CounterMode = TIM_COUNTERMODE_UP;
  htim12.Init.Period = 65535;
  htim12.Init.ClockDivision = TIM_CLOCKDIVISION_DIV1;
  htim12.Init.AutoReloadPreload = TIM_AUTORELOAD_PRELOAD_DISABLE;
  if (HAL_TIM_IC_Init(&htim12) != HAL_OK)
  {
    Error_Handler();
  }
  sMasterConfig.MasterOutputTrigger = TIM_TRGO_RESET;
  sMasterConfig.MasterSlaveMode = TIM_MASTERSLAVEMODE_DISABLE;
  if (HAL_TIMEx_MasterConfigSynchronization(&htim12, &sMasterConfig) != HAL_OK)
  {
    Error_Handler();
  }
  sConfigIC.ICPolarity = TIM_INPUTCHANNELPOLARITY_RISING;
  sConfigIC.ICSelection = TIM_ICSELECTION_DIRECTTI;
  sConfigIC.ICPrescaler = TIM_ICPSC_DIV1;
  sConfigIC.ICFilter = 0;
  if (HAL_TIM_IC_ConfigChannel(&htim12, &sConfigIC, TIM_CHANNEL_1) != HAL_OK)
  {
    Error_Handler();
  }
  if (HAL_TIM_IC_ConfigChannel(&htim12, &sConfigIC, TIM_CHANNEL_2) != HAL_OK)
  {
    Error_Handler();
  }

}

static void MX_TIM15_Init(void)
{

  TIM_MasterConfigTypeDef sMasterConfig = {0};
  TIM_IC_InitTypeDef sConfigIC = {0};

  htim15.Instance = TIM15;
  htim15.Init.Prescaler = 0;
  htim15.Init.CounterMode = TIM_COUNTERMODE_UP;
  htim15.Init.Period = 65535;
  htim15.Init.ClockDivision = TIM_CLOCKDIVISION_DIV1;
  htim15.Init.RepetitionCounter = 0;
  htim15.Init.AutoReloadPreload = TIM_AUTORELOAD_PRELOAD_DISABLE;
  if (HAL_TIM_IC_Init(&htim15) != HAL_OK)
  {
    Error_Handler();
  }
  sMasterConfig.MasterOutputTrigger = TIM_TRGO_RESET;
  sMasterConfig.MasterSlaveMode = TIM_MASTERSLAVEMODE_DISABLE;
  if (HAL_TIMEx_MasterConfigSynchronization(&htim15, &sMasterConfig) != HAL_OK)
  {
    Error_Handler();
  }
  sConfigIC.ICPolarity = TIM_INPUTCHANNELPOLARITY_RISING;
  sConfigIC.ICSelection = TIM_ICSELECTION_DIRECTTI;
  sConfigIC.ICPrescaler = TIM_ICPSC_DIV1;
  sConfigIC.ICFilter = 0;
  if (HAL_TIM_IC_ConfigChannel(&htim15, &sConfigIC, TIM_CHANNEL_1) != HAL_OK)
  {
    Error_Handler();
  }
  if (HAL_TIM_IC_ConfigChannel(&htim15, &sConfigIC, TIM_CHANNEL_2) != HAL_OK)
  {
    Error_Handler();
  }

}

static void MX_USART2_UART_Init(void)
{

  huart2.Instance = USART2;
  huart2.Init.BaudRate = 115200;
  huart2.Init.WordLength = UART_WORDLENGTH_8B;
  huart2.Init.StopBits = UART_STOPBITS_1;
  huart2.Init.Parity = UART_PARITY_NONE;
  huart2.Init.Mode = UART_MODE_TX_RX;
  huart2.Init.HwFlowCtl = UART_HWCONTROL_RTS_CTS;
  huart2.Init.OverSampling = UART_OVERSAMPLING_16;
  huart2.Init.OneBitSampling = UART_ONE_BIT_SAMPLE_DISABLE;
  huart2.Init.ClockPrescaler = UART_PRESCALER_DIV1;
  huart2.AdvancedInit.AdvFeatureInit = UART_ADVFEATURE_NO_INIT;
  if (HAL_UART_Init(&huart2) != HAL_OK)
  {
    Error_Handler();
  }
  if (HAL_UARTEx_SetTxFifoThreshold(&huart2, UART_TXFIFO_THRESHOLD_1_8) != HAL_OK)
  {
    Error_Handler();
  }
  if (HAL_UARTEx_SetRxFifoThreshold(&huart2, UART_RXFIFO_THRESHOLD_1_8) != HAL_OK)
  {
    Error_Handler();
  }
  if (HAL_UARTEx_DisableFifoMode(&huart2) != HAL_OK)
  {
    Error_Handler();
  }

}

static void MX_DMA_Init(void)
{

  /* DMA controller clock enable */
  __HAL_RCC_DMA1_CLK_ENABLE();

  /* DMA interrupt init */
  /* DMA1_Stream0_IRQn interrupt configuration */
  HAL_NVIC_SetPriority(DMA1_Stream0_IRQn, 5, 0);
  HAL_NVIC_EnableIRQ(DMA1_Stream0_IRQn);
  /* DMA1_Stream1_IRQn interrupt configuration */
  HAL_NVIC_SetPriority(DMA1_Stream1_IRQn, 5, 0);
  HAL_NVIC_EnableIRQ(DMA1_Stream1_IRQn);

}

/**
  * Enable MDMA controller clock
  * Configure MDMA for global transfers
  *   hmdma_mdma_channel0_sw_0
  */
static void MX_MDMA_Init(void)
{

  /* MDMA controller clock enable */
  __HAL_RCC_MDMA_CLK_ENABLE();
  /* Local variables */

  /* Configure MDMA channel MDMA_Channel0 */
  /* Configure MDMA request hmdma_mdma_channel0_sw_0 on MDMA_Channel0 */
  hmdma_mdma_channel0_sw_0.Instance = MDMA_Channel0;
  hmdma_mdma_channel0_sw_0.Init.Request = MDMA_REQUEST_SW;
  hmdma_mdma_channel0_sw_0.Init.TransferTriggerMode = MDMA_BUFFER_TRANSFER;
  hmdma_mdma_channel0_sw_0.Init.Priority = MDMA_PRIORITY_LOW;
  hmdma_mdma_channel0_sw_0.Init.Endianness = MDMA_LITTLE_ENDIANNESS_PRESERVE;
  hmdma_mdma_channel0_sw_0.Init.SourceInc = MDMA_SRC_INC_BYTE;
  hmdma_mdma_channel0_sw_0.Init.DestinationInc = MDMA_DEST_INC_BYTE;
  hmdma_mdma_channel0_sw_0.Init.SourceDataSize = MDMA_SRC_DATASIZE_BYTE;
  hmdma_mdma_channel0_sw_0.Init.DestDataSize = MDMA_DEST_DATASIZE_BYTE;
  hmdma_mdma_channel0_sw_0.Init.DataAlignment = MDMA_DATAALIGN_PACKENABLE;
  hmdma_mdma_channel0_sw_0.Init.BufferTransferLength = 1;
  hmdma_mdma_channel0_sw_0.Init.SourceBurst = MDMA_SOURCE_BURST_SINGLE;
  hmdma_mdma_channel0_sw_0.Init.DestBurst = MDMA_DEST_BURST_SINGLE;
  hmdma_mdma_channel0_sw_0.Init.SourceBlockAddressOffset = 0;
  hmdma_mdma_channel0_sw_0.Init.DestBlockAddressOffset = 0;
  if (HAL_MDMA_Init(&hmdma_mdma_channel0_sw_0) != HAL_OK)
  {
    Error_Handler();
  }

  /* MDMA interrupt initialization */
  /* MDMA_IRQn interrupt configuration */
  HAL_NVIC_SetPriority(MDMA_IRQn, 5, 0);
  HAL_NVIC_EnableIRQ(MDMA_IRQn);

}

static void MX_GPIO_Init(void)
{
  GPIO_InitTypeDef GPIO_InitStruct = {0};

  /* GPIO Ports Clock Enable */
  __HAL_RCC_GPIOE_CLK_ENABLE();
  __HAL_RCC_GPIOH_CLK_ENABLE();
  __HAL_RCC_GPIOC_CLK_ENABLE();
  __HAL_RCC_GPIOA_CLK_ENABLE();
  __HAL_RCC_GPIOB_CLK_ENABLE();
  __HAL_RCC_GPIOD_CLK_ENABLE();

  /*Configure GPIO pin Output Level */
  HAL_GPIO_WritePin(GPIOB, GPIO_PIN_0|BSE_F_Pin|GPS_PWR2_Pin|GPS_PWR1_Pin, GPIO_PIN_RESET);

  /*Configure GPIO pin Output Level */
  HAL_GPIO_WritePin(BRAKE_L_GPIO_Port, BRAKE_L_Pin, GPIO_PIN_RESET);

  /*Configure GPIO pin Output Level */
  HAL_GPIO_WritePin(GPIOD, BSE_R_Pin|MAster_Control_Pin|RTD_Button_DIGI_Pin, GPIO_PIN_RESET);

  /*Configure GPIO pin Output Level */
  HAL_GPIO_WritePin(GPIOE, GPIO_PIN_1, GPIO_PIN_RESET);

  /*Configure GPIO pins : PB0 BSE_F_Pin GPS_PWR2_Pin GPS_PWR1_Pin */
  GPIO_InitStruct.Pin = GPIO_PIN_0|BSE_F_Pin|GPS_PWR2_Pin|GPS_PWR1_Pin;
  GPIO_InitStruct.Mode = GPIO_MODE_OUTPUT_PP;
  GPIO_InitStruct.Pull = GPIO_NOPULL;
  GPIO_InitStruct.Speed = GPIO_SPEED_FREQ_LOW;
  HAL_GPIO_Init(GPIOB, &GPIO_InitStruct);

  /*Configure GPIO pin : BRAKE_L_Pin */
  GPIO_InitStruct.Pin = BRAKE_L_Pin;
  GPIO_InitStruct.Mode = GPIO_MODE_OUTPUT_PP;
  GPIO_InitStruct.Pull = GPIO_NOPULL;
  GPIO_InitStruct.Speed = GPIO_SPEED_FREQ_LOW;
  HAL_GPIO_Init(BRAKE_L_GPIO_Port, &GPIO_InitStruct);

  /*Configure GPIO pins : BSE_R_Pin MAster_Control_Pin RTD_Button_DIGI_Pin */
  GPIO_InitStruct.Pin = BSE_R_Pin|MAster_Control_Pin|RTD_Button_DIGI_Pin;
  GPIO_InitStruct.Mode = GPIO_MODE_OUTPUT_PP;
  GPIO_InitStruct.Pull = GPIO_NOPULL;
  GPIO_InitStruct.Speed = GPIO_SPEED_FREQ_LOW;
  HAL_GPIO_Init(GPIOD, &GPIO_InitStruct);

  /*Configure GPIO pin : PE1 */
  GPIO_InitStruct.Pin = GPIO_PIN_1;
  GPIO_InitStruct.Mode = GPIO_MODE_OUTPUT_PP;
  GPIO_InitStruct.Pull = GPIO_NOPULL;
  GPIO_InitStruct.Speed = GPIO_SPEED_FREQ_LOW;
  HAL_GPIO_Init(GPIOE, &GPIO_InitStruct);

}

void StartDefaultTask(void *argument)
{
  for(;;)
  {
    osDelay(1);
  }
}

void StartADCTask(void *argument)
{
  /* USER CODE BEGIN StartADCTask */
  HAL_ADCEx_MultiModeStart_DMA(&hadc1, (uint32_t*) raw, 16);
  /* Infinite loop */
  for(;;)
  {
    adc1 = raw[0] & 0xFFFF;
    adc2 = raw[0] >> 16;
    vTaskDelay(1);
  }
  /* USER CODE END StartADCTask */
}

 /* MPU Configuration */

void MPU_Config(void)
{
  MPU_Region_InitTypeDef MPU_InitStruct = {0};

  /* Disables the MPU */
  HAL_MPU_Disable();

  /** Initializes and configures the Region and the memory to be protected
  */
  MPU_InitStruct.Enable = MPU_REGION_ENABLE;
  MPU_InitStruct.Number = MPU_REGION_NUMBER0;
  MPU_InitStruct.BaseAddress = 0x0;
  MPU_InitStruct.Size = MPU_REGION_SIZE_4GB;
  MPU_InitStruct.SubRegionDisable = 0x87;
  MPU_InitStruct.TypeExtField = MPU_TEX_LEVEL0;
  MPU_InitStruct.AccessPermission = MPU_REGION_FULL_ACCESS;
  MPU_InitStruct.DisableExec = MPU_INSTRUCTION_ACCESS_DISABLE;
  MPU_InitStruct.IsShareable = MPU_ACCESS_SHAREABLE;
  MPU_InitStruct.IsCacheable = MPU_ACCESS_CACHEABLE;
  MPU_InitStruct.IsBufferable = MPU_ACCESS_NOT_BUFFERABLE;

  HAL_MPU_ConfigRegion(&MPU_InitStruct);
  /* Enables the MPU */
  HAL_MPU_Enable(MPU_PRIVILEGED_DEFAULT);

}

void HAL_TIM_PeriodElapsedCallback(TIM_HandleTypeDef *htim)
{
  if (htim->Instance == TIM3)
  {
    HAL_IncTick();
  }
}

void Error_Handler(void)
{
  __disable_irq();
  while (1)
  {
  }
}
